# IWRL6432 register map
File version: 1.0
CPU: CM4 1.0, other endian, MPU, FPU, 3 interrupt priority bits
Registers are 32-bit, read-write, reset 0x0 unless marked. A register's access mark holds for its fields unless they carry their own. Offsets are from the block's base; [hi:lo] are bit positions.

## APP_I2C
Base 0x57F7F800
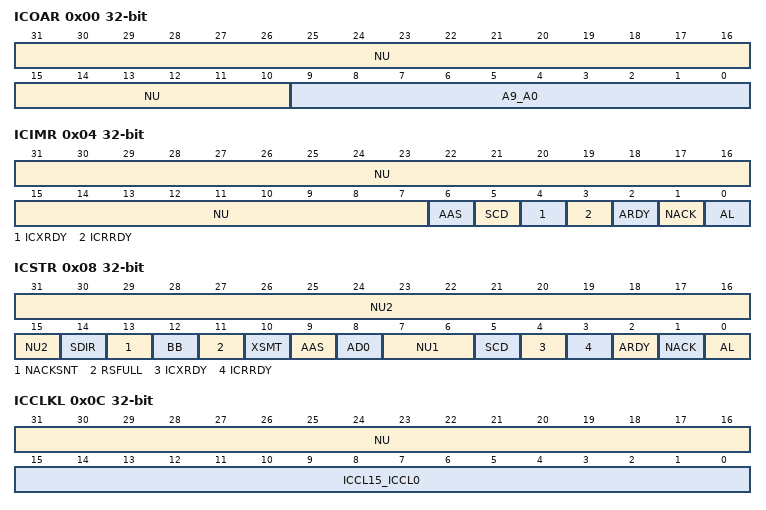
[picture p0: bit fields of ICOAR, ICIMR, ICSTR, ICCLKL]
0x00 ICOAR — I2C Own Address register
  [31:10] NU — [31:10] Reserved
  [9:0] A9_A0 — [9:0] Own address. Use in both 7- and 10-bit address mode. Note that usercan program the I2C own address to any value as long as it does notconflict with other components in the system.
0x04 ICIMR — I2C Interrupt Mask/Status register
  [31:7] NU — [31:7] Reserved
  [6] AAS — [6:6] Address As Slave interrupt mask bit. Setting a"1" to this bit unmasks the Address As Slave interrupt. Setting a"0" to this bit masks the Address As Slave interrupt.
  [5] SCD — [5:5] Stop Condition Detection mask bit. Setting a"1" to this bit unmasks the Stop Condition Detection interrupt. Setting a "0" to this bit masks the Stop Condition Detection interrupt.
  [4] ICXRDY — [4:4] Transmit Data Ready interrupt mask bit. Setting a"1" to this bit unmasks the Transmit Data Ready interrupt. Setting a"0" to this bit masks the Transmit Data Ready interrupt.
  [3] ICRRDY — [3:3] Receive Data Ready interrupt mask bit. Setting a"1" to this bit unmasks the Receive Data Ready interrupt. Setting a"0" to this bit masks the Receive Data Ready interrupt.
  [2] ARDY — [2:2] Register access ready interrupt mask bit. Setting a"1" to this bit unmasks the Register access ready interrupt. Setting a"0" to this bit masks the Register access ready interrupt.
  [1] NACK — [1:1] No Acknowledgement interrupt mask bit. Setting a"1" to this bit unmasks the No Acknowledgement interrupt. Setting a"0" to this bit masks the No Acknowledgement interrupt.
  [0] AL — [0:0] Arbitration Lost interrupt mask bit. Setting a"1" to this bit unmasks the Arbitration Lost interrupt. Setting a"0" to this bit masks the Arbitration Lost interrupt.
0x08 ICSTR — I2C Interrupt Status register
  [31:15] NU2 — [31:15] Reserved
  [14] SDIR — [14:14] Slave Direction. This bit is clear to '0' indicating the I2C is a master transmitter/receiver or a slave receiver. This bit is also clear by STOP condition or START condition. It is set to '1' when the I2C slave is a transmitter. In DLB mode (which the configuration should be master-transmitter slave-receiver) this bit is clear to '0'. Writing a"1" to this bit to clear it.
  [13] NACKSNT — [13:13] A No Acknowledge is sent due to NACKMOD is set to a"1". NACKSNT =0: A No Acknowledge is not sent. NACKSNT =1: A No Acknowledge is sent. Writing a"1" to this bit to clear it.
  [12] BB — [12:12] Bus Busy. This bit indicates the state of the serial bus. BB=0: The bus is free. BB=1: The bus is occupied. On reception of a"start" condition the device sets BB to 1. This bit is also set if the I2C detects SCL low state. BB is clear to 0 after reception of a"stop" condition. BB is kept to"0" regardless SCL state when the I2C is in reset (IRS_=0). If the IRS_ is set to"1" during transaction between other I2C devices the BB bit is set at the first falling edge of SCL or START condition. - (RW )
  [11] RSFULL — [11:11] Receive shift full. This bit indicates whether the receiver has experienced overrun. Overrun occurs when the receive shift register (ICRSR) is full and ICDRR has not been read since the ICRSR-to-ICDRR transfer. The FSM is holding for ICDRR read access. RSFULL is clear when reading the ICDRR. RSFULL is set to"1" when the I2C has recognized an overrun. The contents of ICDRR are NOT lost in this case. In repeat mode since double buffer (ICRSR and ICDRR) behaves like a single buffer RSFULL is set to"1" every time the data is received. RSFULL is clear as a result of reading the ICDRR. - (RW )
  [10] XSMT — [10:10] Transmit shift empty not. This bit indicates whether the transmitter has experienced underflow. Underflow occurs when the transmit shift register (ICXSR) is empty and ICDXR has not been loaded. The FSM is holding for ICDXR write access. XSMT_ is cleared when underflow has occurred. XSMT_ is set to"1" as a result of writing to ICDXR. In repeat mode if the I2C in master transmitter mode is holding transfer with XSMT_=0 (i.e. waiting for further action) and the STT or STP bit is set XSMT_ is set to"1" by hardware.
  [9] AAS — [9:9] Address As Slave. This bit is set to 1 by the device when it has recognized its own slave address or an address of all (8) zeros. The AAS bit is reset by stop condition or detection of any address byte that does not match ICOAR. - (RW )
  [8] AD0 — [8:8] Address Zero Status: This bit is set to 1 by device if it detects the address of all (8) zeros (i.e. general call). The AD0 bit is reset to 0 (default value) when a"start" or"stop" condition is detected. - (RW )
  [7:6] NU1 — [7:6] Reserved
  [5] SCD — [5:5] Stop Condition Detection bit SCD is set when the I2C sends or receives STOP condition. This bit is cleared by reading ICIVR (as 110) or writing '1' to itself.
  [4] ICXRDY — [4:4] Transmit Data Ready interrupt flag bit. ICXRDY is set to"1" is generated when the transmitted data has been copied from ICDXR to the transmit-shift register (ICXSR). ICRXDY is clear to"0" when the ICDXR is written. This bit can also be polled by the CPU to write a new transmitted data into the ICDXR. Write '1' to this bit will set it and DXR Write will clear it.
  [3] ICRRDY — [3:3] Receive Data Ready interrupt flag bit. ICRRDY is set to"1" when the received data has been copied from ICRSR into the ICDRR. ICRRDY is cleared to"0" when the ICDRR is read. This bit can also be polled by the CPU to read the received data in the ICDRR. Write '1' or DRR Read will clear it.
  [2] ARDY — [2:2] Register-access-ready interrupt flag bit. ARDY is generated by the hardware if the I2C is in the master mode when the previously programmed data and command has been performed and status bit has been updated. This flag is used by the CPU to let it knows that the I2C registers are ready to be accessed again. When RM=0 ARDY is set when the internal data count is passed 0 if STP register bit has not been set. When RM=1 ARDY is set at each byte end. If the I2C is in FDF mode(FDF=1) ARDY is set just after Start condition. This bit is automatically cleared by hardware when writing data to ICDXR in transmit mode reading data from ICDRR in receive mode or setting STT or STP bit. Write '1' will clear it.
  [1] NACK — [1:1] No-Acknowledgement interrupt flag bit. The No Acknowledge flag bit is set when the hardware in "master" mode detects no acknowledge has been received. This bit is NOT set by no-acknowledgement after Start byte Write '1' or Read the ICIVR (as 010) will clear it.
  [0] AL — [0:0] Arbitration-Lost interrupt flag bit. The Arbitration Lost flag bit is set to 1 when the device in the "master" mode senses it has lost an arbitration when two or more transmitters start a transmission almost simultaneously or when the I2C attempts to start a transfer while BB (bus busy) is 1. When this is set to 1 due to arbitration lost the MST/STT/STP bits are clear the I2C becomes a slave. Write '1' or Read the ICIVR (as 001) will clear it.
0x0C ICCLKL — I2C Clock Divider Low register
  [31:16] NU — [31:16] Reserved
  [15:0] ICCL15_ICCL0 — [15:0] Low time I 2 C SCL Clock Division Factor. They are used to divide down the master clock to create the SCL low time transition frequency. This register must be configured while the I2C is still in reset (IRS_=0).
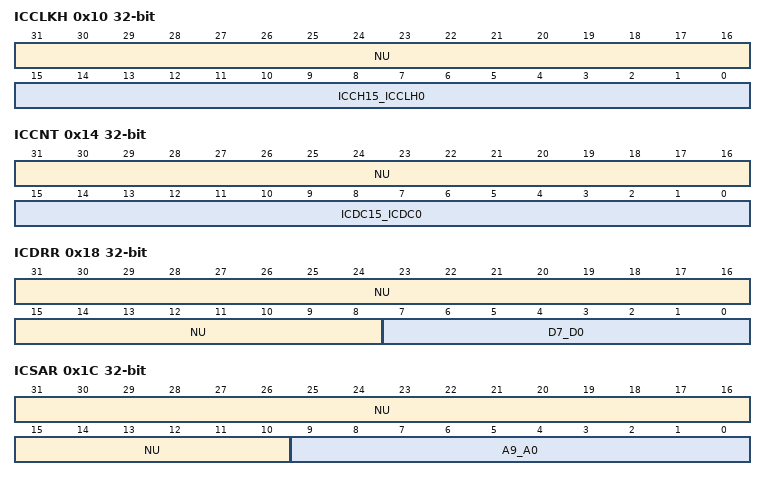
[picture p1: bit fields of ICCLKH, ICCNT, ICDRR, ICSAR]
0x10 ICCLKH — I2C Clock Divider High register
  [31:16] NU — [31:16] Reserved
  [15:0] ICCH15_ICCLH0 — [15:0] High time I 2 C SCL Clock Division Factor. They are used to divide down the master clock to create the SCL high time transition frequency. This register must be configured while the I2C is still in reset (IRS_=0).
0x14 ICCNT — I2C Data Count register
  [31:16] NU — [31:16] Reserved
  [15:0] ICDC15_ICDC0 — [15:0] Data count. This data count register is used to generate a Stop condition if a Stop condition is specified (STP=1). . ICCNT=1 data count is 1 :::::::::::::::::::::::::::::::::::::::::::: :::::::::::::::::::::::::::::::::::::::::::: ICCNT=0FFFFh data count is 65535 ICCNT=0data counter is 65536 Note that ICCNT is a don"t care when RM is set to 1.
0x18 ICDRR — I2C Data Receive register
  [31:8] NU — [31:8] Reserved
  [7:0] D7_D0 — [7:0] Receive data
0x1C ICSAR — I2C Slave Address register
  [31:10] NU — [31:10] Reserved
  [9:0] A9_A0 — [9:0] Slave address. Use in both 7- and 10-bit address mode.
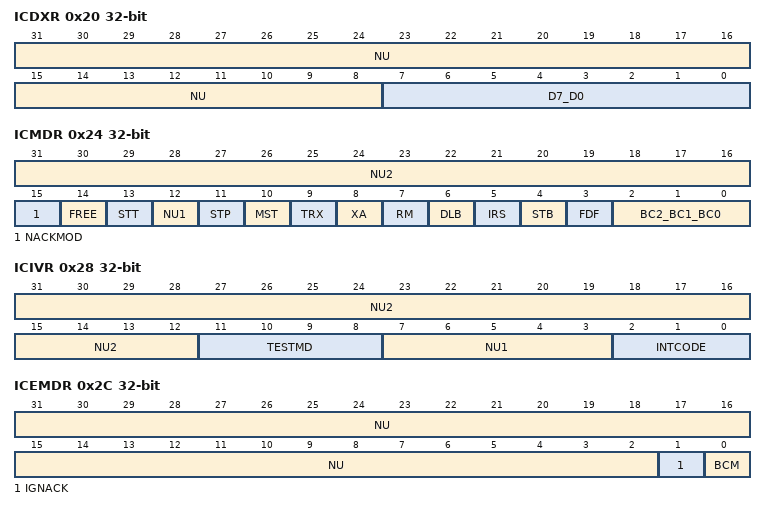
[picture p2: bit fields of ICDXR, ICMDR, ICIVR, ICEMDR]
0x20 ICDXR — I2C Data Transmit register
  [31:8] NU — [31:8] Reserved
  [7:0] D7_D0 — [7:0] Transmit data
0x24 ICMDR — I2C Mode register
  [31:16] NU2 — [31:16] Reserved
  [15] NACKMOD — [15:15] No Acknowledge (NACK) mode. This bit is used to send an Acknowledge (ACK) or a No Acknowledge (NACK) to the transmitter. This bit is only applicable when the I2C is in receiver mode. In master receiver mode when the internal data count counter decrements to zero the I2C sends a NACK. The master receiver I2C finishes a transfer when it sends a NACK. The I2C ignores ICCNT when NACKMOD is '1'. The NACKMOD bit should be set before the rising edge of the last data bit (bit 8) if a NACK must be sent and this bit is cleared once a NACK has been sent. NACKMOD=0 the I2C sends an ACK to the transmitter during the acknowledge cycle. NACKMOD=1 the I2C sends a NACK to the transmitter during the acknowledge cycle.
  [14] FREE — [14:14] Free Running. This bit is used to determine the state of the I2C when a breakpoint is encountered in the HLL debugger. FREE=0: (default) Stops immediately if SCL is low and keep driving SCL low whether I2C is master transmitter/receiver. If SCL is high I2C waits until SCL becomes low and then stops. If the I2C is a slave it will stop when the transmission/receiving completes. FREE=1: The I2C runs free.
  [13] STT — [13:13] Start Condition (Master only mode). This bit can be set to a"1" by the CPU to generate a Start condition. In master mode when setting Start to"1" generates a Start condition. It is reset to "0" by the hardware after the Start condition has been generated. The Start/Stop bits can be configured to generate different transfer formats. Note that the STT and STP can be used to terminate the repeat mode. ____________________________________________________ STT___STP____Conditions_______________Bus Activities _1_____0________Start___________________S-A-D _0_____1________Stop_____________________P _1_____1________Start-Stop (ICCNT= n)______S-A-D..(n)..D-P _1_____0________Start (ICCNT= n)__________S-A-D..(n)..D ____________________________________________________
  [12] NU1 — [12:12] Reserved for IDLEEN (IDLE Enable on 5509). - (RW )
  [11] STP — [11:11] Stop Condition (Master mode only). This bit can be set to a"1" by the CPU to generate a Stop condition. It is reset to "0" by the hardware after the Stop condition has been generated. The Stop condition is generated when ICCNT passes 0 when the I2C is in non-repeat mode(RM=0).
  [10] MST — [10:10] Master. MST=0: The I 2 C peripheral is in the"slave" mode and clock is received from the"master" device. MST=1: The I 2 C peripheral is in the"master" mode and it generates the clock. This bit is clear when the transfer completed.
  [9] TRX — [9:9] Transmitter. TRX=0: The I 2 C is in the"receiver" mode and data on data line SDA is shifted into the data register ICDRR. TRX=1: The I 2 C is in the"transmitter" mode and the data in ICDXR is shifted out on data line SDA. The operating modes (not in FDF mode) are defined as follows. In FDF mode TRX must be configured even if the I2C is in slave mode because there is no address/direction byte in FDF mode. ______________________________ MST___TRX___Operating Modes _0______x_____"slave receiver" _0______x_____"slave transmitter" _1______0_____"master receiver" _1______1_____"master transmitter" ______________________________
  [8] XA — [8:8] Expanded Address. XA=0: (default) 7-bit address mode (normal address mode). XA=1: 10-bit address mode (expanded address mode) Please note that XA needs to be configured even if the I2C is in slave mode.
  [7] RM — [7:7] Repeat Mode. This bit is set to a"1" by the CPU to put the I2C in the repeat mode. In this mode data is continuously transmitted out of the ICDXR until the STP bit is set to"1" regardless of ICCNT value. This bit is don"t care if the I2C is configured in slave mode. _________________________________________________________ RM___STT___STP___Conditions_____Bus Activities_______Mode _0_____0_____0_______Idle___________None___________NA _0_____0_____1_______Stop____________P____________NA _0_____1_____0_____(Re)Start_______S-A-D..(n)..D____Repeat n _0_____1_____1_____(Re)Start-Stop___S-A-D..(n)..D-P__Repeat n _1_____0_____0_______Idle___________none___________NA _1_____0_____1_______Stop____________P ___________NA _1_____1_____0_____(Re)Start_______S-A-D-D-D.._____Continuous _1_____1_____1_____Reserved________None___________NA _________________________________________________________
  [6] DLB — [6:6] Digital Loop Back (in master transmit mode only). This bit is set to a"1" by the CPU to put the I2C in the loop back mode. In this mode data transmitted out of the ICDXR will be received in the ICDRR after ((CPU freq/I2C freq)8) CPU cycles via an internal path. The address of the ICOAR is output on SDA.
  [5] IRS — [5:5] I2C Reset Not. This can be set to a"0" by the CPU to put the I2C in reset or to a"1" to take the I2C out of reset. When this bit is reset to 0 all status bits in ICSTR and ICIVR are set to default values. Note that if this bit is reset during a transfer it can cause the I2C bus hang (SDA and SCL are tri-stated).
  [4] STB — [4:4] Start Byte (Master only mode). The Start Byte mode bit is set to 1 by the CPU to configure the I2C in Start byte mode the I2C sends "00000001"∩┐╜ regardless ICSAR value. Refer to the Philip I2C spec for more details.
  [3] FDF — [3:3] Free Data Format. This bit can be set to"1" by the CPU to configure the I2C in Free Data Format mode. ______________________________________________ FDF___MST___TRX______Operating mode _0______0_____ x____Slave in non FDF mode _0______1_____0____Master receive in non FDF mode _0______1_____1____Master transmit in non FDF mode _1______0_____0____Slave receiver in FDF mode _1______0_____1____Slave transmitter in FDF mode _1______1_____0____Master receiver in FDF mode _1______1_____1____Master transmitter in FDF mode ______________________________________________
  [2:0] BC2_BC1_BC0 — [2:0] Bit Count : Bit Count 2, Bit Count 1 and Bit Count 0 define the number of bits starting from the lsb (excluding the acknowledge bit) of the next byte which are yet to be received or transmitted. __________________________________________ BC2_BC1_BC0__Bits/byte in FDF__Bits/byte w/ ACK _0___0___1_____NA (reserved)____ NA (reserved) _0___1___0________2______________3_______ _0___1___1________3______________4_______ _1___0___0________4______________5_______ _1___0___1________5______________6_______ _1___1___0________6______________7_______ _1___1___1________7______________8_______ _0___0___0________8______________9_______ __________________________________________
0x28 ICIVR — I2C Interrupt Vector register
  [31:12] NU2 — [31:12] Reserved.
  [11:8] TESTMD — [11:8] Reserved for internal testing.
  [7:3] NU1 — [7:3] Reserved.
  [2:0] INTCODE — [2:0] Interrupt code. The binary-coded-interrupt vector indicates which interrupt has occurred. Reading the ICIVR clears the interrupt code except ARDY(011) RRDY(100) and XRDY(101). Interrupt code for ARDY RRDY and XRDY is cleared when ARDY ICRRDY and ICXRDY bits in the ICSTR is cleared to default value respectively. If other interrupts are pending a new interrupt is generated. If there are more than one interrupt flag reading the ICIVR clears the highest priority interrupt code. Reading the ICIVR also clears corresponding status bit in the ICSTR except ARDY ICRRDY ICXRDY and AAS. Note that users must read (clear) the ICIVR before doing another start otherwise the ICIVR could contain incorrect (old interrupt flags) value. ________________________________________________ Interrupt Code____________Interrupt Occurred__________ _000_(default)_________________None _001_(highest priority)____Arbitration Lost interrupt _010__________________No Acknowledgement interrupt _011__________________Register Access Ready interrupt _100__________________Receive Data Ready interrupt _101__________________Transmit Data Ready interrupt _110__________________Stop Condition Detection _111_(lowest priority)_____Address As Slave - (RW) ________________________________________________
0x2C ICEMDR — I2C Extended Mode register
  [31:2] NU — [31:2] Reserved. - (RW )
  [1] IGNACK — [1:1] Ignore NACK mode IGNACK=0 The master transmitter will operate normally discontinue the data transfer and set the ARDY and NACK status bits when a NACK signal is received from the slave. IGNACK=1 The master transmitter will ignore a NACK received from the slave.
  [0] BCM — [0:0] Backward Compatibility Mode. This bit affects the I2C interrupt behavior. Refer to appendix A for details.
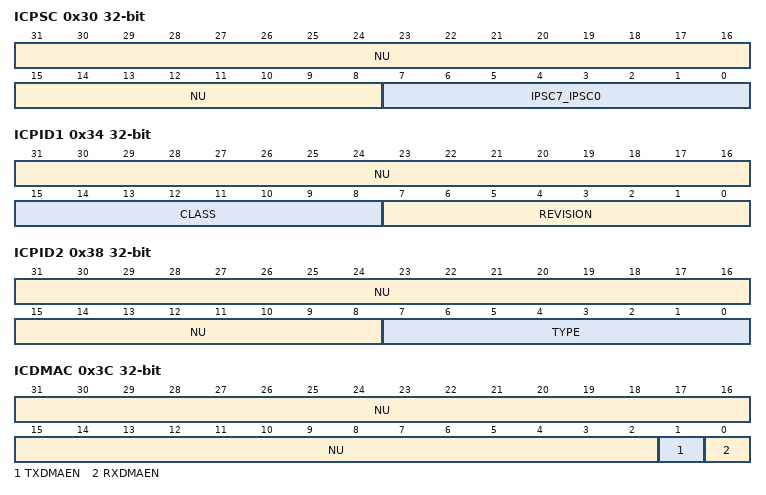
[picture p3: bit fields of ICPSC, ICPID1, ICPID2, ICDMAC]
0x30 ICPSC — I2C Prescaler register
  [31:8] NU — [31:8] Reserved.
  [7:0] IPSC7_IPSC0 — [7:0] 8-bit prescaler to divide the system clock down to 4/8/12Mhz clock and used by the I2C module. This register must be initialized while the I2C is still in reset (IRS_=0). The value takes effect on the rising edge of IRS_.
0x34 ICPID1 — I2C Peripheral ID register 1
  [31:16] NU — [31:16] Reserved.
  [15:8] CLASS — [15:8] Identifies the class of peripheral. This value should be 0x01 - (RW )
  [7:0] REVISION — [7:0] Identifies the revision level of the I2C. This value should be incremented each time the design is revised. - (RW )
0x38 ICPID2 — I2C Peripheral ID register 2
  [31:8] NU — [31:8] Reserved.
  [7:0] TYPE — [7:0] Identifies the type of peripheral. This value should be 0x05 - (RW )
0x3C ICDMAC — I2C DMA Control Register
  [31:2] NU — [31:2] Reserved. - (RW )
  [1] TXDMAEN — [1:1] Transmit DMA enable. This bit controls the receive DMA event pin to the system. When this bit is 1 the DMA event is enabled and ICTEVT_POR pin is asserted when the DMA transfer is required. When this bit is 0 the ICTEVT_POR pin is never asserted. RXDMAEN=0: DMA transmit event is disabled. RXDMAEN=1: DMA transmit event is enabled. (Default)
  [0] RXDMAEN — [0:0] Receive DMA enable. This bit controls the receive DMA event pin to the system. When this bit is 1 the DMA event is enabled and ICREVT_POR pin is asserted when the DMA transfer is required. When this bit is 0 the ICREVT_POR pin is never asserted. RXDMAEN=0: DMA receive event is disabled. RXDMAEN=1: DMA receive event is enabled. (Default)
0x40 I2C_RESERVED1 — Reserved
  [31:0] NU — [31:0] Reserved.
0x44 I2C_RESERVED2 — Reserved
  [31:0] NU — [31:0] Reserved.
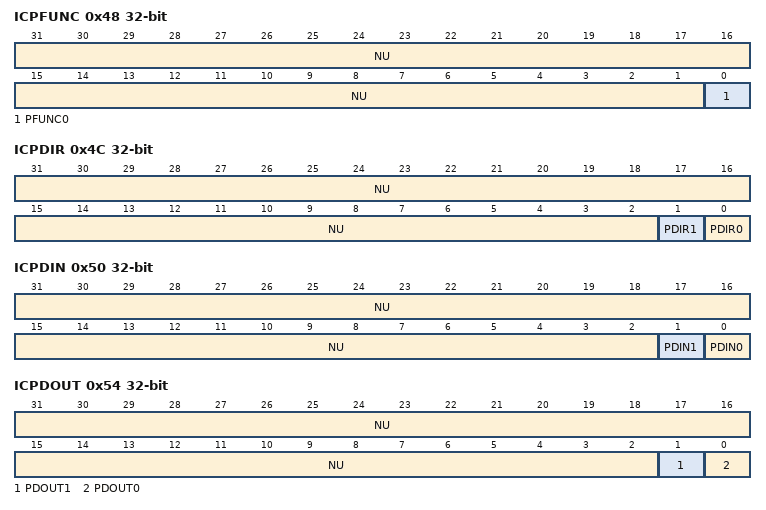
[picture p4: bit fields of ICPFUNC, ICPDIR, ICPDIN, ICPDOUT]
0x48 ICPFUNC — I2C Pin Function register
  [31:1] NU — [31:1] Reserved.
  [0] PFUNC0 — [0:0] Controls the function of the I2C SCL and SDA pins. 0 = Pins function as SCL and SDA 1 = Pins functions as GPIO Note: No hardware protection is required to disable I2C function when the PFUNC[0] and IRS_ bits are both set to one. When PFUNC[0] is"1" (GPIO mode) the sub-module which controls the I2C function receives the value"1" for SCL and SDA. IRS_ can be set to"1" regardless of PFUNC[0] and the I2C function works whenever the IRS_ bit is"1". The user is expected to hold I2C in reset via IRS_ bit when changing to/from GPIO mode via the PFUNC[0] bit.
0x4C ICPDIR — I2C Pin Direction register
  [31:2] NU — [31:2] Reserved
  [1] PDIR1 — [1:1] Controls the direction of the I2C SDA pin when configured as GPIO. 0 = SDA pin functions as input 1 = SDA pin functions as output
  [0] PDIR0 — [0:0] Controls the direction of the I2C SCL pin when configured as GPIO. 0 = SCL pin functions as input 1 = SCL pin functions as output
0x50 ICPDIN — I2C Pin Data In register
  [31:2] NU — [31:2] Reserved
  [1] PDIN1 — [1:1] Indicates the logic level present on the SDA pin. Reads: 0 = Logic low present at SDA pin regardless of PFUNC setting. 1 = Logic high present at SDA pin regardless of PFUNC setting. Writes: Writes have no effect. - (RW )
  [0] PDIN0 — [0:0] Indicates the logic level present on the SCL pin. Reads: 0 = Logic low present at SCL pin regardless of PFUNC setting. 1 = Logic high present at SCL pin regardless of PFUNC setting. Writes: Writes have no effect - (RW )
0x54 ICPDOUT — I2C Pin Data Out register
  [31:2] NU — [31:2] Reserved
  [1] PDOUT1 — [1:1] Controls the level driven on the SDA pin when configured as GPIO output. Reads: Reads return register values not GPIO pin levels. Writes: 0 = SDA pin driven low 1 = SDA pin driven high. Note: If SDA is connected to an open-drain buffer at the chiplevel the I2C cannot drive SDA to high.
  [0] PDOUT0 — [0:0] Controls the level driven on the SCL pin when configured as GPIO output. Reads: Reads return register values not GPIO pin levels. Writes: 0 = SCL pin driven low 1 = SCL pin driven high Note: If SCL is connected to an open-drain buffer at the chiplevel the I2C cannot drive SCL to high.
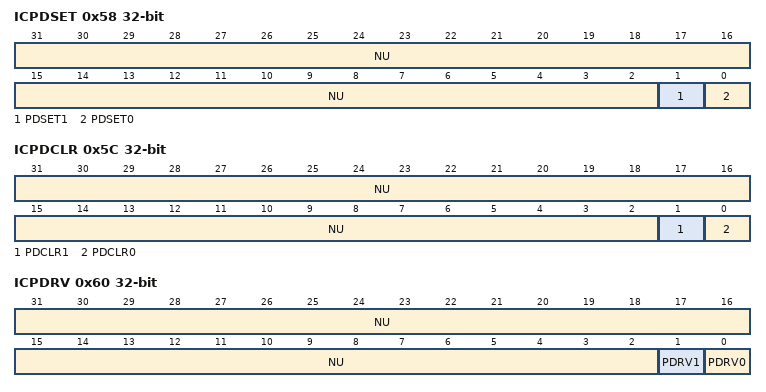
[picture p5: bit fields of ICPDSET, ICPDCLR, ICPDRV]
0x58 ICPDSET — I2C Pin Data Set register
  [31:2] NU — [31:2] Reserved
  [1] PDSET1 — [1:1] Used to set PDOUT[1] bit which corresponds to the SDA GPIO pin. Reads: Reads should return 0. User documentation should say reads are indeterminate. Writes: 0 = no effect 1 = PDOUT[1] bit is set to logic high.
  [0] PDSET0 — [0:0] Used to set PDOUT[0] bit which corresponds to the SCL GPIO pin. Reads: Reads should return 0. User documentation should say reads are indeterminate. Writes: 0 = no effect 1 = PDOUT[0] bit is set to logic high.
0x5C ICPDCLR — I2C Pin Data Clear register
  [31:2] NU — [31:2] Reserved
  [1] PDCLR1 — [1:1] Used to clear PDOUT[1] bit which corresponds to the SDA pin. Reads: Reads should return 0. User documentation should say reads are indeterminate. Writes: 0 = no effect 1 = PDOUT[1] bit is cleared to logic low.
  [0] PDCLR0 — [0:0] Used to clear PDOUT[0] bit which corresponds to the SCL pin. Reads: Reads should return 0. User documentation should say reads are indeterminate. Writes: 0 = no effect 1 = PDOUT[0] bit is cleared to logic low.
0x60 ICPDRV — I2C Pin Driver Mode Register
  [31:2] NU — [31:2] Reserved
  [1] PDRV1 — [1:1] Used to select driver mode of output buffer for SDA pin. 0 = I2C mode. 1 = GPIO mode. Note: Value of this register is reflected on the PDRV_SDA_POR port. Actual function depends on I/O buffer and chip implementation.
  [0] PDRV0 — [0:0] Used to select driver mode of output buffer for SCL pin. 0 = I2C mode. 1 = GPIO mode. Note: Value of this register is reflected on the PDRV_SCL_POR port. Actual function depends on I/O buffer and chip implementation.
